# STM32L010C6T6 register map
File version: 1.0
Registers are 32-bit, access not given, reset 0x0 unless marked. A register's access mark holds for its fields unless they carry their own. Offsets are from the block's base; [hi:lo] are bit positions; {n}, {i} and the like mark numbered series; 'fields as' and 'values as' point back to an identical list.

## DMA1
Base 0x40020000
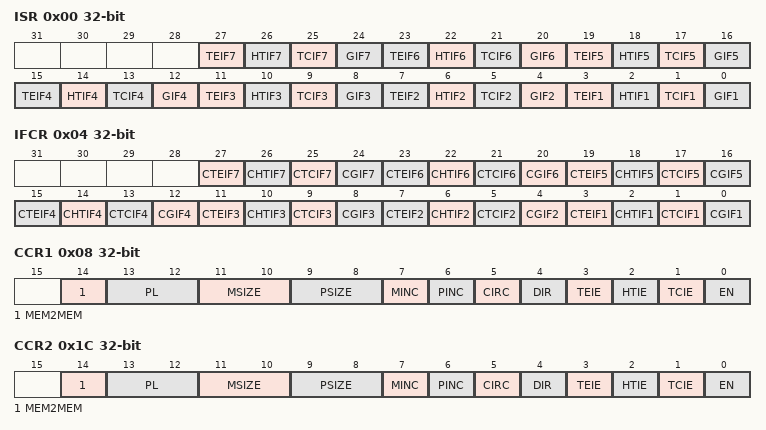
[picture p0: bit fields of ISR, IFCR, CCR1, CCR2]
0x00 ISR
  [4n-1] TEIF{n} (n=1..7), [4n-2] HTIF{n} (n=1..7), [4n-3] TCIF{n} (n=1..7), [4n-4] GIF{n} (n=1..7)
0x04 IFCR
  [4n-1] CTEIF{n} (n=1..7), [4n-2] CHTIF{n} (n=1..7), [4n-3] CTCIF{n} (n=1..7), [4n-4] CGIF{n} (n=1..7)
0x08 CCR1
  [14] MEM2MEM, [13:12] PL, [11:10] MSIZE, [9:8] PSIZE, [7] MINC, [6] PINC, [5] CIRC, [4] DIR, [3] TEIE, [2] HTIE, [1] TCIE, [0] EN
0x0C CNDTR1
  [15:0] NDTR
0x10 CPAR1
  [31:0] PA
{0x0+0x14*i} CMAR{i} (i=1..7)
  [31:0] MA
0x1C CCR2
  fields as CCR1
0x20 CNDTR2
  [15:0] NDTR
0x24 CPAR2
  [31:0] PA
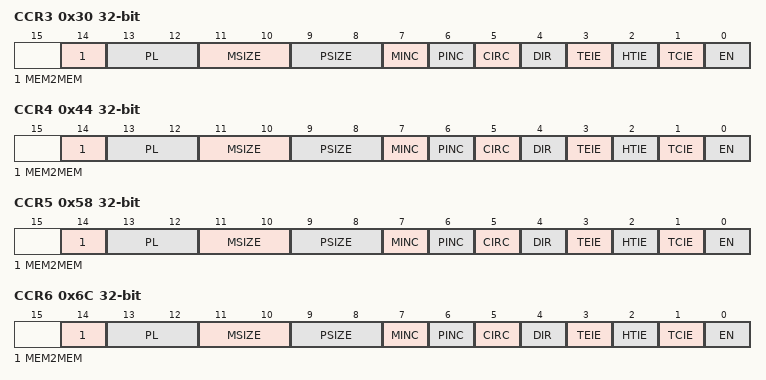
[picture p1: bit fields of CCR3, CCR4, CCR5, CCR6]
0x30 CCR3
  fields as CCR1
0x34 CNDTR3
  [15:0] NDTR
0x38 CPAR3
  [31:0] PA
0x44 CCR4
  fields as CCR1
0x48 CNDTR4
  [15:0] NDTR
0x4C CPAR4
  [31:0] PA
0x58 CCR5
  fields as CCR1
0x5C CNDTR5
  [15:0] NDTR
0x60 CPAR5
  [31:0] PA
0x6C CCR6
  fields as CCR1
0x70 CNDTR6
  [15:0] NDTR
0x74 CPAR6
  [31:0] PA
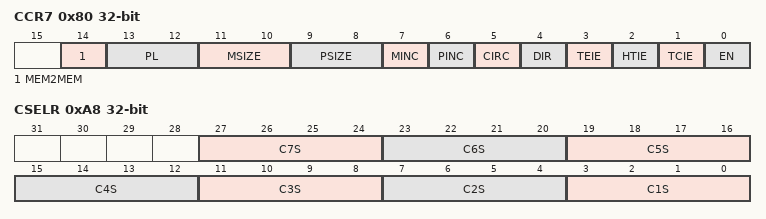
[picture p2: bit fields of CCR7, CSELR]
0x80 CCR7
  fields as CCR1
0x84 CNDTR7
  [15:0] NDTR
0x88 CPAR7
  [31:0] PA
0xA8 CSELR
  [4n-1:4n-4] C{n}S (n=1..7)

## RCC
Base 0x40021000
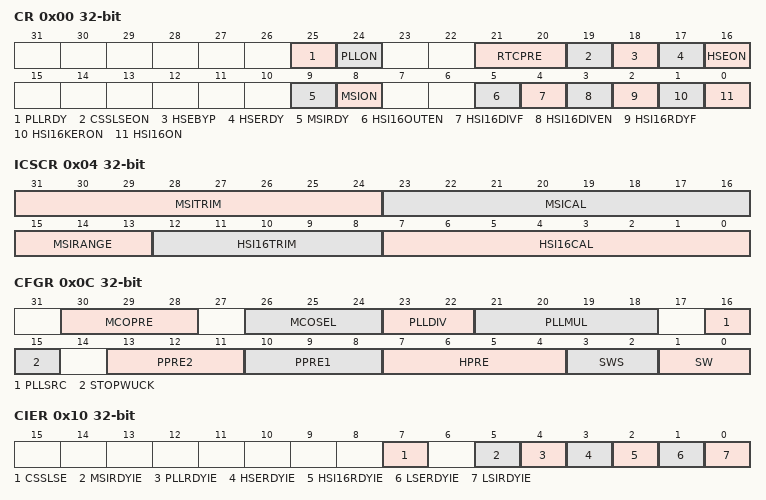
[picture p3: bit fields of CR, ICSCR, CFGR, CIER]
0x00 CR
  [25] PLLRDY, [24] PLLON, [21:20] RTCPRE, [19] CSSLSEON, [18] HSEBYP, [17] HSERDY, [16] HSEON, [9] MSIRDY, [8] MSION, [5] HSI16OUTEN, [4] HSI16DIVF, [3] HSI16DIVEN, [2] HSI16RDYF, [1] HSI16KERON, [0] HSI16ON
0x04 ICSCR
  [31:24] MSITRIM, [23:16] MSICAL, [15:13] MSIRANGE, [12:8] HSI16TRIM, [7:0] HSI16CAL
0x0C CFGR
  [30:28] MCOPRE, [26:24] MCOSEL, [23:22] PLLDIV, [21:18] PLLMUL, [16] PLLSRC, [15] STOPWUCK, [13:11] PPRE2, [10:8] PPRE1, [7:4] HPRE, [3:2] SWS, [1:0] SW
0x10 CIER
  [7] CSSLSE, [5] MSIRDYIE, [4] PLLRDYIE, [3] HSERDYIE, [2] HSI16RDYIE, [1] LSERDYIE, [0] LSIRDYIE
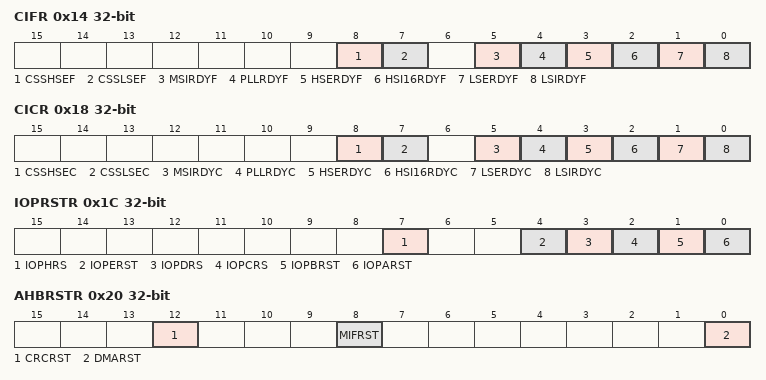
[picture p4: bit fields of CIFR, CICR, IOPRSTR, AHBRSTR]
0x14 CIFR
  [8] CSSHSEF, [7] CSSLSEF, [5] MSIRDYF, [4] PLLRDYF, [3] HSERDYF, [2] HSI16RDYF, [1] LSERDYF, [0] LSIRDYF
0x18 CICR
  [8] CSSHSEC, [7] CSSLSEC, [5] MSIRDYC, [4] PLLRDYC, [3] HSERDYC, [2] HSI16RDYC, [1] LSERDYC, [0] LSIRDYC
0x1C IOPRSTR
  [7] IOPHRS, [4] IOPERST, [3] IOPDRS, [2] IOPCRS, [1] IOPBRST, [0] IOPARST
0x20 AHBRSTR
  [12] CRCRST, [8] MIFRST, [0] DMARST
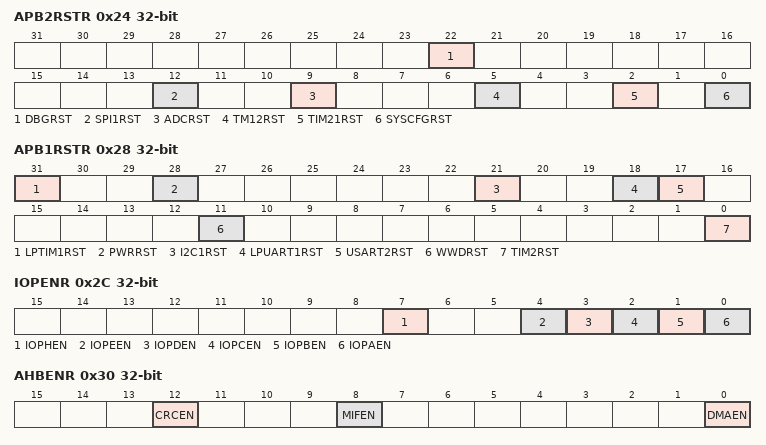
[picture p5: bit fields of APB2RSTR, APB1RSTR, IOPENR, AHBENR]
0x24 APB2RSTR
  [22] DBGRST, [12] SPI1RST, [9] ADCRST, [5] TM12RST, [2] TIM21RST, [0] SYSCFGRST
0x28 APB1RSTR
  [31] LPTIM1RST, [28] PWRRST, [21] I2C1RST, [18] LPUART1RST, [17] USART2RST, [11] WWDRST, [0] TIM2RST
0x2C IOPENR
  [7] IOPHEN, [4] IOPEEN, [3] IOPDEN, [2] IOPCEN, [1] IOPBEN, [0] IOPAEN
0x30 AHBENR
  [12] CRCEN, [8] MIFEN, [0] DMAEN
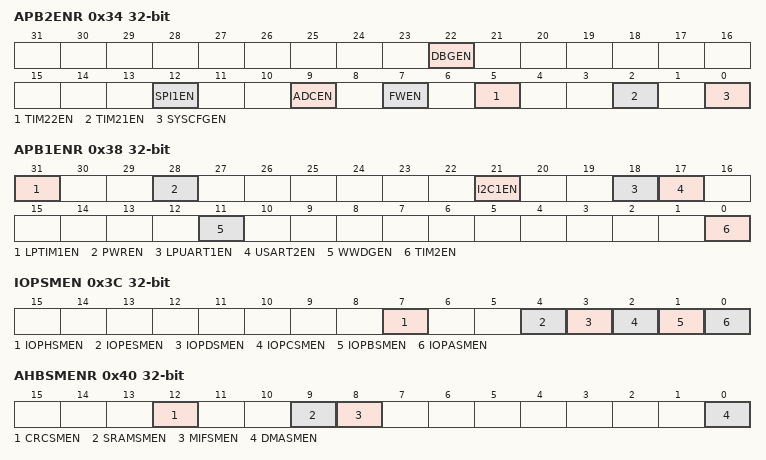
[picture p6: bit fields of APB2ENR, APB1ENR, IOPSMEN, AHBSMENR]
0x34 APB2ENR
  [22] DBGEN, [12] SPI1EN, [9] ADCEN, [7] FWEN, [5] TIM22EN, [2] TIM21EN, [0] SYSCFGEN
0x38 APB1ENR
  [31] LPTIM1EN, [28] PWREN, [21] I2C1EN, [18] LPUART1EN, [17] USART2EN, [11] WWDGEN, [0] TIM2EN
0x3C IOPSMEN
  [7] IOPHSMEN, [4] IOPESMEN, [3] IOPDSMEN, [2] IOPCSMEN, [1] IOPBSMEN, [0] IOPASMEN
0x40 AHBSMENR
  [12] CRCSMEN, [9] SRAMSMEN, [8] MIFSMEN, [0] DMASMEN
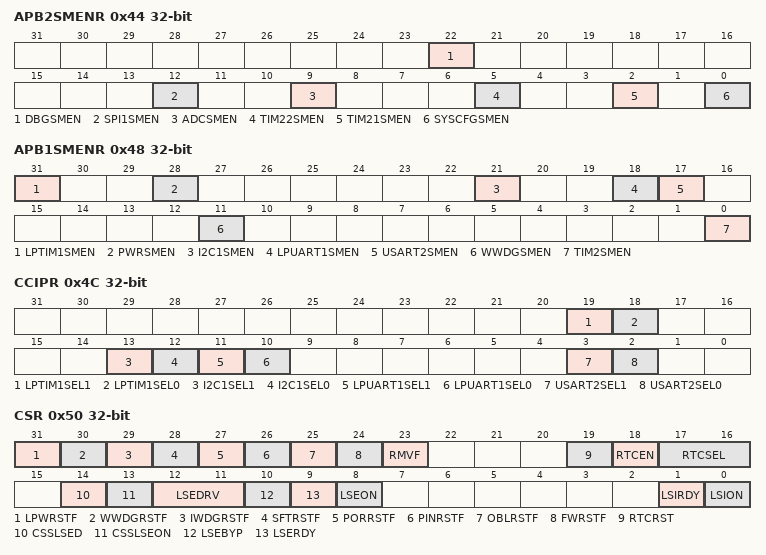
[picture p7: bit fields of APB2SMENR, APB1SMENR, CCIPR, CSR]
0x44 APB2SMENR
  [22] DBGSMEN, [12] SPI1SMEN, [9] ADCSMEN, [5] TIM22SMEN, [2] TIM21SMEN, [0] SYSCFGSMEN
0x48 APB1SMENR
  [31] LPTIM1SMEN, [28] PWRSMEN, [21] I2C1SMEN, [18] LPUART1SMEN, [17] USART2SMEN, [11] WWDGSMEN, [0] TIM2SMEN
0x4C CCIPR
  [19] LPTIM1SEL1, [18] LPTIM1SEL0, [13] I2C1SEL1, [12] I2C1SEL0, [11] LPUART1SEL1, [10] LPUART1SEL0, [3] USART2SEL1, [2] USART2SEL0
0x50 CSR
  [31] LPWRSTF, [30] WWDGRSTF, [29] IWDGRSTF, [28] SFTRSTF, [27] PORRSTF, [26] PINRSTF, [25] OBLRSTF, [24] FWRSTF, [23] RMVF, [19] RTCRST, [18] RTCEN, [17:16] RTCSEL, [14] CSSLSED, [13] CSSLSEON, [12:11] LSEDRV, [10] LSEBYP, [9] LSERDY, [8] LSEON, [1] LSIRDY, [0] LSION

## FLASH
Base 0x40022000
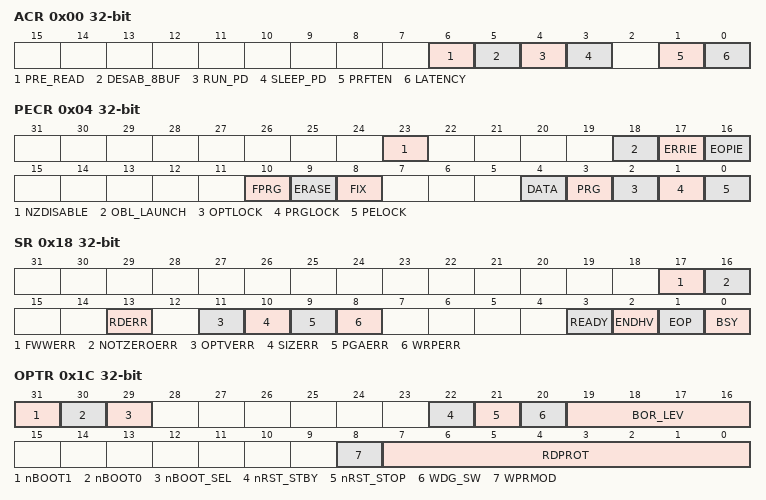
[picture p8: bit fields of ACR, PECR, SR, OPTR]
0x00 ACR
  [6] PRE_READ, [5] DESAB_8BUF, [4] RUN_PD, [3] SLEEP_PD, [1] PRFTEN, [0] LATENCY
0x04 PECR
  [23] NZDISABLE, [18] OBL_LAUNCH, [17] ERRIE, [16] EOPIE, [10] FPRG, [9] ERASE, [8] FIX, [4] DATA, [3] PRG, [2] OPTLOCK, [1] PRGLOCK, [0] PELOCK
0x08 PDKEYR
0x0C PKEYR
0x10 PRGKEYR
0x14 OPTKEYR
0x18 SR
  [17] FWWERR, [16] NOTZEROERR, [13] RDERR, [11] OPTVERR, [10] SIZERR, [9] PGAERR, [8] WRPERR, [3] READY, [2] ENDHV, [1] EOP, [0] BSY
0x1C OPTR
  [31] nBOOT1, [30] nBOOT0, [29] nBOOT_SEL, [22] nRST_STBY, [21] nRST_STOP, [20] WDG_SW, [19:16] BOR_LEV, [8] WPRMOD, [7:0] RDPROT
0x20 WRPROT1
0x80 WRPROT2
  [15:0] WRPROT2

## CRC
Base 0x40023000
0x00 DR
0x04 IDR
  [7:0] IDR
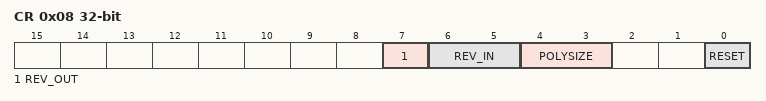
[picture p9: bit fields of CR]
0x08 CR
  [7] REV_OUT, [6:5] REV_IN, [4:3] POLYSIZE, [0] RESET
0x10 INIT
  [31:0] CRC_INIT
0x14 POL

## GPIOA
Base 0x50000000
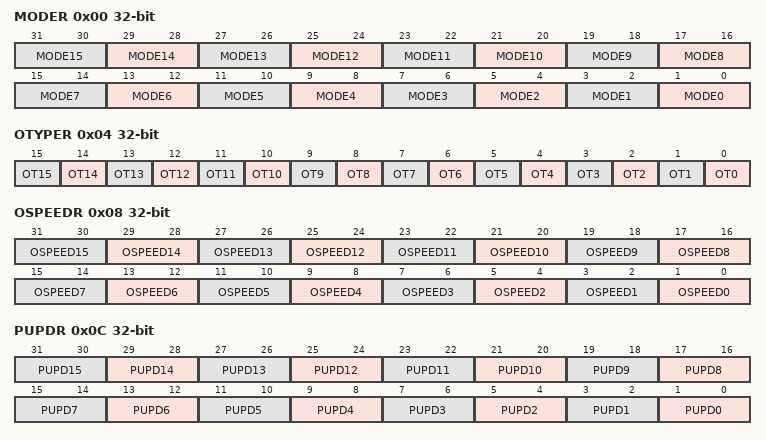
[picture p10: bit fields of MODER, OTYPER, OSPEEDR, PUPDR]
0x00 MODER
  [2n+1:2n] MODE{n} (n=0..15)
0x04 OTYPER
  [n] OT{n} (n=0..15)
0x08 OSPEEDR
  [2n+1:2n] OSPEED{n} (n=0..15)
0x0C PUPDR
  [2n+1:2n] PUPD{n} (n=0..15)
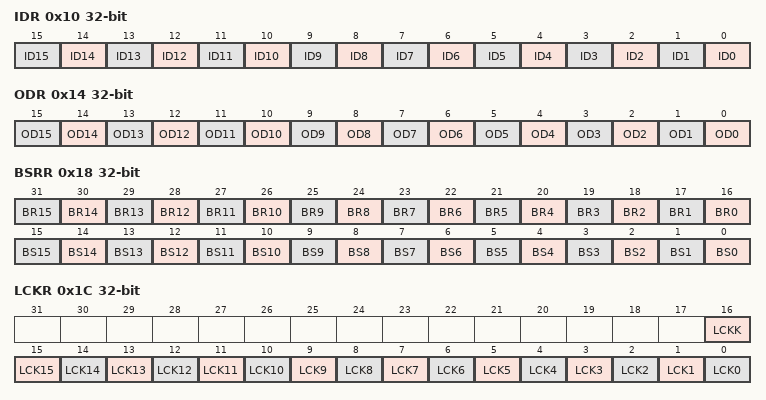
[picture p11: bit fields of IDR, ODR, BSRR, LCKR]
0x10 IDR
  [n] ID{n} (n=0..15)
0x14 ODR
  [n] OD{n} (n=0..15)
0x18 BSRR
  [n+16] BR{n} (n=0..15), [n] BS{n} (n=0..15)
0x1C LCKR
  [16] LCKK, [n] LCK{n} (n=0..15)
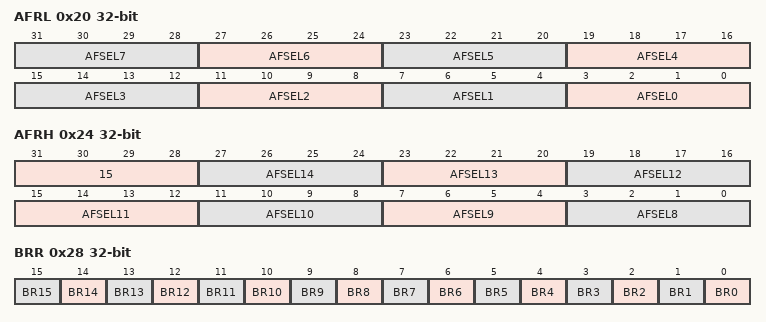
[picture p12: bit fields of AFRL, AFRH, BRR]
0x20 AFRL
  [4n+3:4n] AFSEL{n} (n=0..7)
0x24 AFRH
  [31:28] 15, [4n-29:4n-32] AFSEL{n} (n=8..14)
0x28 BRR
  [n] BR{n} (n=0..15)

## GPIOB
Base 0x50000400
Same registers: GPIOC 0x50000800, GPIOD 0x50000C00, GPIOE 0x50001000, GPIOH 0x50001C00
Registers as GPIOA, without PUPDR; these are added or differ:
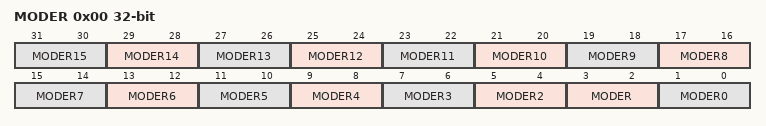
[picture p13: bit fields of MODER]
0x00 MODER
  [2n+1:2n] MODER{n} (n=2..15), [3:2] MODER, [1:0] MODER0
